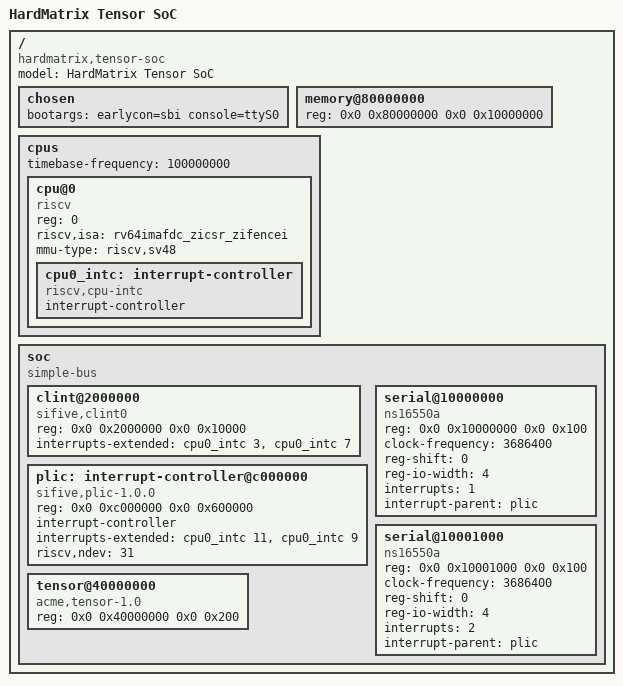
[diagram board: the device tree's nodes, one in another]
// Device tree for HardMatrix Tensor SoC (matches renode/platform.repl)
// RISC-V 64-bit, PLIC, CLINT, dual NS16550 UART, Verilator-cosim VAM

/dts-v1/;

/ {
    #address-cells = <2>;
    #size-cells = <2>;
    compatible = "hardmatrix,tensor-soc";
    model = "HardMatrix Tensor SoC";

    chosen {
        bootargs = "earlycon=sbi console=ttyS0";
    };

    memory@80000000 {
        device_type = "memory";
        reg = <0x0 0x80000000 0x0 0x10000000>;  /* 256 MB */
    };

    cpus {
        #address-cells = <1>;
        #size-cells = <0>;
        timebase-frequency = <100000000>;

        cpu@0 {
            device_type = "cpu";
            reg = <0>;
            compatible = "riscv";
            riscv,isa = "rv64imafdc_zicsr_zifencei";
            mmu-type = "riscv,sv48";

            cpu0_intc: interrupt-controller {
                #interrupt-cells = <1>;
                compatible = "riscv,cpu-intc";
                interrupt-controller;
            };
        };
    };

    soc {
        #address-cells = <2>;
        #size-cells = <2>;
        compatible = "simple-bus";
        ranges;

        clint@2000000 {
            compatible = "sifive,clint0", "riscv,clint0";
            reg = <0x0 0x2000000 0x0 0x10000>;
            interrupts-extended = <&cpu0_intc 3>, <&cpu0_intc 7>;
        };

        plic: interrupt-controller@c000000 {
            compatible = "sifive,plic-1.0.0", "riscv,plic0";
            reg = <0x0 0xc000000 0x0 0x600000>;
            #address-cells = <0>;
            #interrupt-cells = <1>;
            interrupt-controller;
            interrupts-extended = <&cpu0_intc 11>, <&cpu0_intc 9>;
            riscv,ndev = <31>;
        };

        /* Console UART — uart0 in Renode */
        serial@10000000 {
            compatible = "ns16550a";
            reg = <0x0 0x10000000 0x0 0x100>;
            clock-frequency = <3686400>;
            reg-shift = <0>;
            reg-io-width = <4>;
            interrupts = <1>;
            interrupt-parent = <&plic>;
        };

        /* Data UART — uart1 in Renode, used by relay */
        serial@10001000 {
            compatible = "ns16550a";
            reg = <0x0 0x10001000 0x0 0x100>;
            clock-frequency = <3686400>;
            reg-shift = <0>;
            reg-io-width = <4>;
            interrupts = <2>;
            interrupt-parent = <&plic>;
        };

        /* Vector Adder Machine — Verilator co-simulated */
        tensor@40000000 {
            compatible = "acme,tensor-1.0";
            reg = <0x0 0x40000000 0x0 0x200>;
        };
    };
};
